# PER_CM register map
Vendor: Texas Instruments
Peripheral module from a debugger description file (folder omap36xx).
Registers are 32-bit, access per field, reset 0x0 unless marked. A register's access mark holds for its fields unless they carry their own. Offsets are as the file gives them; lines under a group give offsets from that group; [hi:lo] are bit positions; {n}, {i} and the like mark numbered series; 'fields as' and 'values as' point back to an identical list; <NAME> marks a mode.

## PER_CM
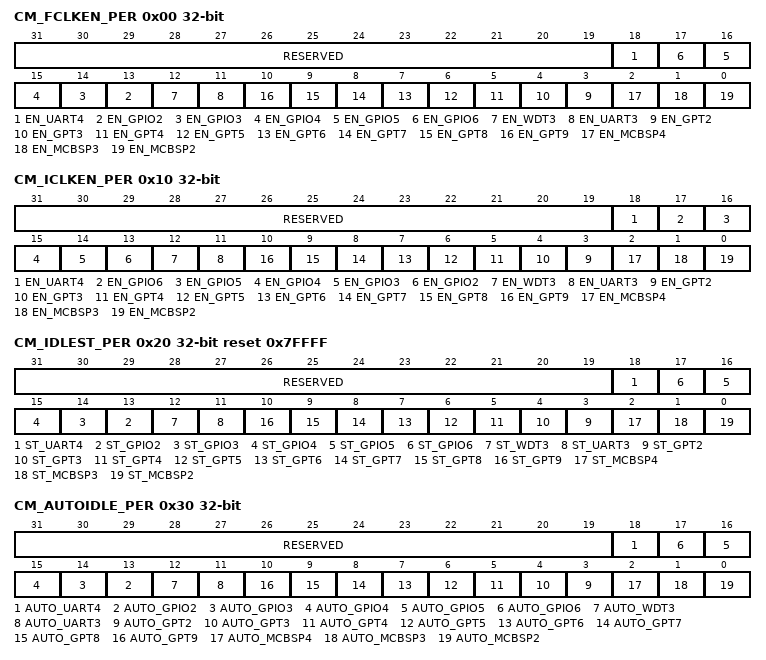
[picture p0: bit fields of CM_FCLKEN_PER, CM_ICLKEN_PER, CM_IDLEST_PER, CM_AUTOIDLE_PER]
0x00 CM_FCLKEN_PER — Controls the modules functional clock activity.
  [31:19] RESERVED ro — Write 0s for future compatibility. Read returns 0.
  [18] EN_UART4 rw — UART4 functional clock control.
    0=UART 4 functional clock is disabled; 1=UART 4 functional clock is enabled
  [n+11] EN_GPIO{n} rw (n=2..6) — GPIO {n} functional clock control
    0=GPIO {n} functional clock is disabled; 1=GPIO {n} functional clock is enabled
  [12] EN_WDT3 rw — WDTIMER 3 functional clock control.
    0=WDTIMER 3 functional clock is disabled; 1=WDTIMER 3 functional clock is enabled
  [11] EN_UART3 rw — UART3 functional clock control.
    0=UART 3 functional clock is disabled; 1=UART 3 functional clock is enabled
  [n+1] EN_GPT{n} rw (n=2..9) — GPTIMER {n} functional clock control.
    0=GPTIMER {n} functional clock is disabled; 1=GPTIMER {n} functional clock is enabled
  [2] EN_MCBSP4 rw — McBSP 4 functional clock control.
    0=McBSP 4 functional clock is disabled; 1=McBSP 4 functional clock is enabled
  [1] EN_MCBSP3 rw — McBSP3 functional clock control.
    0=McBSP 3 functional clock is disabled; 1=McBSP 3 functional clock is enabled
  [0] EN_MCBSP2 rw — McBSP 2 functional clock control.
    0=McBSP 2 functional clock is disabled; 1=McBSP 2 functional clock is enabled
0x10 CM_ICLKEN_PER — Controls the modules interface clock activity.
  [31:19] RESERVED ro — Write 0s for future compatibility. Read returns 0.
  [18] EN_UART4 rw — UART4 interface clock control.
    0=UART 4 interface clock is disabled; 1=UART 4 interface clock is enabled
  [17] EN_GPIO6 rw — GPIO 6 interface clock control
    0=GPIO 6 interface clock is disabled; 1=GPIO 6 interface clock is enabled
  [16] EN_GPIO5 rw — GPIO 5 interface clock control
    0=GPIO 5 interface clock is disabled; 1=GPIO 5 interface clock is enabled
  [15] EN_GPIO4 rw — GPIO 4 interfface clock control
    0=GPIO 4 interface clock is disabled; 1=GPIO 4 interface clock is enabled
  [14] EN_GPIO3 rw — GPIO 3 interface clock control
    0=GPIO 3 interface clock is disabled; 1=GPIO 3 interface clock is enabled
  [13] EN_GPIO2 rw — GPIO 2 interface clock control
    0=GPIO 2 interface clock is disabled; 1=GPIO 2 interface clock is enabled
  [12] EN_WDT3 rw — WDTIMER 3 interface clock control.
    0=WDTIMER 3 interface clock is disabled; 1=WDTIMER 3 interface clock is enabled
  [11] EN_UART3 rw — UART3 interface clock control.
    0=UART 3 interface clock is disabled; 1=UART 3 interface clock is enabled
  [n+1] EN_GPT{n} rw (n=2..9) — GPTIMER {n} interface clock control.
    0=GPTIMER {n} interface clock is disabled; 1=GPTIMER {n} interface clock is enabled
  [2] EN_MCBSP4 rw — McBSP 4 interface clock control.
    0=McBSP 4 interface clock is disabled; 1=McBSP 4 interface clock is enabled
  [1] EN_MCBSP3 rw — McBSP 3 interface clock control.
    0=McBSP 3 interface clock is disabled; 1=McBSP 3 interface clock is enabled
  [0] EN_MCBSP2 rw — McBSP 2 interface clock control.
    0=McBSP 2 interface clock is disabled; 1=McBSP 2 interface clock is enabled
0x20 CM_IDLEST_PER ro reset 0x7FFFF — Modules access availability monitoring. This register is read only and automatically updated.
  [31:19] RESERVED — Read returns 0.
  [18] ST_UART4 — UART4 idle status.
    0=UART 4 can be accessed; 1=UART 4 cannot be accessed. Any access may return an error.
  [n+11] ST_GPIO{n} (n=2..6) — GPIO {n} idle status
    0=GPIO {n} can be accessed; 1=GPIO {n} cannot be accessed. Any access may return an error.
  [12] ST_WDT3 — WDTIMER 3 idle status.
    0=WDTIMER 3 can be accessed; 1=WDTIMER 3 cannot be accessed. Any access may return an error.
  [11] ST_UART3 — UART3 idle status.
    0=UART 3 can be accessed; 1=UART 3 cannot be accessed. Any access may return an error.
  [n+1] ST_GPT{n} (n=2..9) — GPTIMER {n} idle status.
    0=GPTIMER {n} can be accessed; 1=GPTIMER {n} cannot be accessed. Any access may return an error.
  [2] ST_MCBSP4 — McBSP 4 idle status.
    0=McBSP 4 can be accessed; 1=McBSP 4 cannot be accessed. Any access may return an error.
  [1] ST_MCBSP3 — McBSP 3 idle status.
    0=McBSP 3 can be accessed; 1=McBSP 3 cannot be accessed. Any access may return an error.
  [0] ST_MCBSP2 — McBSP 2 idle status.
    0=McBSP 2 can be accessed; 1=McBSP 2 cannot be accessed. Any access may return an error.
0x30 CM_AUTOIDLE_PER — This register controls the automatic control of the modules interface clock activity.
  [31:19] RESERVED ro — Write 0s for future compatibility. Read returns 0.
  [18] AUTO_UART4 rw — UART4 auto clock control.
    0=UART 4 interface clock is unrelated to the domain state transition; 1=UART 4 interface clock is automatically enabled or disabled along with the domain state transition
  [n+11] AUTO_GPIO{n} rw (n=2..6) — GPIO {n} auto clock control
    0=GPIO {n} interface clock is unrelated to the domain state transition; 1=GPIO {n} interface clock is automatically enabled or disabled along with the domain state transition
  [12] AUTO_WDT3 rw — WDTIMER 3 auto clock control.
    0=WDTIMER 3 interface clock is unrelated to the domain state transition; 1=WDTIMER 3 interface clock is automatically enabled or disabled along with the domain state transition
  [11] AUTO_UART3 rw — UART3 auto clock control.
    0=UART 3 interface clock is unrelated to the domain state transition; 1=UART 3 interface clock is automatically enabled or disabled along with the domain state transition
  [n+1] AUTO_GPT{n} rw (n=2..9) — GPTIMER {n} auto clock control.
    0=GPTIMER {n} interface clock is unrelated to the domain state transition; 1=GPTIMER {n} interface clock is automatically enabled or disabled along with the domain state transition
  [2] AUTO_MCBSP4 rw — McBSP 4 auto clock control.
    0=McBSP 4 interface clock is unrelated to the domain state transition; 1=McBSP 4 interface clock is automatically enabled or disabled along with the domain state transition
  [1] AUTO_MCBSP3 rw — McBSP 3 auto clock control.
    0=McBSP 3 interface clock is unrelated to the domain state transition; 1=McBSP 3 interface clock is automatically enabled or disabled along with the domain state transition
  [0] AUTO_MCBSP2 rw — McBSP 2 auto clock control.
    0=McBSP 2 interface clock is unrelated to the domain state transition; 1=McBSP 2 interface clock is automatically enabled or disabled along with the domain state transition
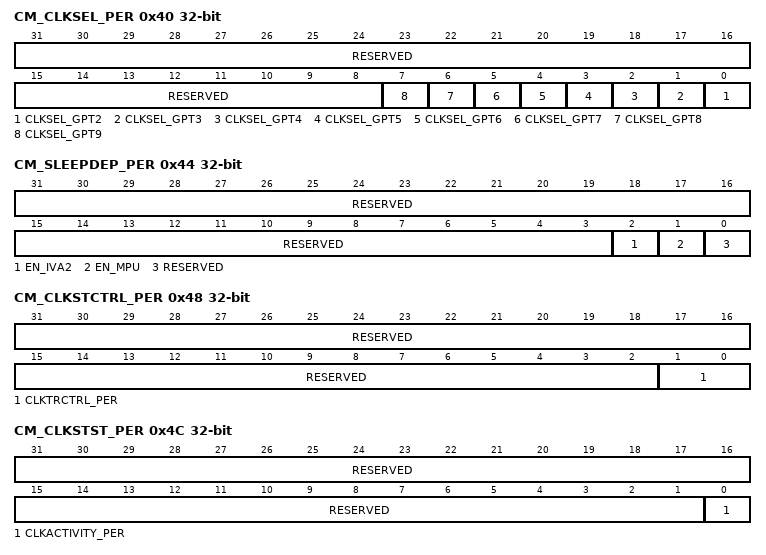
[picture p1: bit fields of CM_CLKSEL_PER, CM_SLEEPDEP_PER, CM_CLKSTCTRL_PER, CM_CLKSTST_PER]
0x40 CM_CLKSEL_PER — PER domain modules source clock selection.
  [31:8] RESERVED ro — Write 0s for future compatibility. Read returns 0.
  [n-2] CLKSEL_GPT{n} rw (n=2..9) — Selects GPTIMER {n} source clock
    0=source is 32K_FCLK; 1=source is SYS_CLK
0x44 CM_SLEEPDEP_PER — This register allows enabling or disabling the sleep transition dependency of PER domain with respect to other domain.
  [31:3] RESERVED ro — Write 0s for future compatibility. Read returns 0.
  [2] EN_IVA2 rw — IVA2 domain dependency
    0=PER domain sleep dependency with IVA2 domain is disabled; 1=PER domain sleep dependency with IVA2 domain is enabled
  [1] EN_MPU rw — MPU domain dependency
    0=PER domain sleep dependency with MPU domain is disabled; 1=PER domain sleep dependency with MPU domain is enabled
  [0] RESERVED rw — Write 0s for future compatibility. Read returns 0.
0x48 CM_CLKSTCTRL_PER — This register enables the domain power state transition. It controls the HW supervised domain power state transition between ACTIVE and INACTIVE states.
  [31:2] RESERVED ro — Write 0s for future compatibility. Read returns 0.
  [1:0] CLKTRCTRL_PER rw — Controls the clock state transition of the PERIPHERAL clock domain.
    0=Automatic transition is disabled; 1=Start a software supervised sleep transition on the domain; 2=Start a software supervised wake-up transition on the domain; 3=Automatic transition is enabled. Transition is supervised by the HardWare.
0x4C CM_CLKSTST_PER ro — This register provides a status on the OCP interface clock activity in the domain.
  [31:1] RESERVED — Write 0s for future compatibility. Read returns 0.
  [0] CLKACTIVITY_PER — Interface clock activity status
    0=No domain interface clock activity; 1=Domain interface clock is active
